# ARMv8M-Baseline register map
Registers are read-only, no defined reset value unless marked. A register's access mark holds for its fields unless they carry their own. Offsets are from the block's base; [hi:lo] are bit positions; {n}, {i} and the like mark numbered series.

## DWT — Data Watchpoint and Trace
Base 0xE0001000
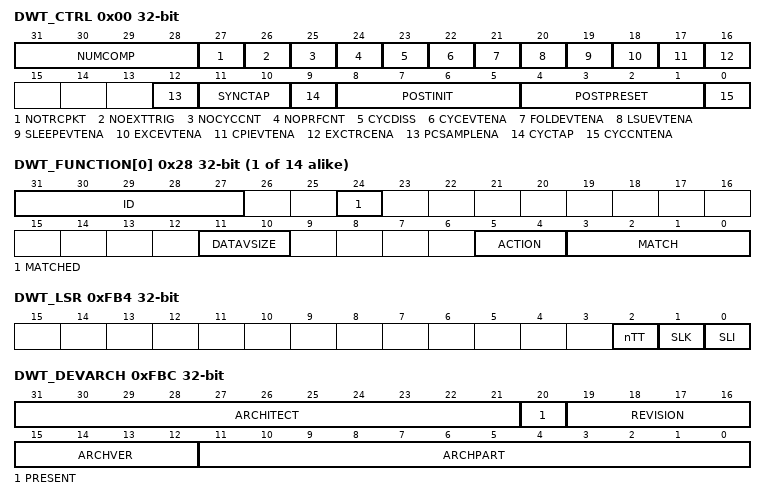
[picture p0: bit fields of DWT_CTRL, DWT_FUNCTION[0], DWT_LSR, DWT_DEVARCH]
0x00 DWT_CTRL rw — Data Watchpoint Trace Control Register provides configuration and status information and control of the unit
  [31:28] NUMCOMP — Number of comparators. Number of DWT comparators implemented
  [27] NOTRCPKT — No trace packets. Indicates whether the implementation does not support trace
    0=Trace supported; 1=Trace not supported
  [26] NOEXTTRIG — No External Triggers. Shows whether the implementation does not support external triggers
  [25] NOCYCCNT — No cycle count. Indicates whether the implementation does not include a cycle counter
    0=Cycle counter implemented; 1=Cycle counter not implemented
  [24] NOPRFCNT — No profile counters. Indicates whether the implementation does not include the profiling counters
    0=Profiling counters implemented; 1=Profiling counters not implemented
  [23] CYCDISS — Cycle counter disabled secure. Controls whether the cycle counter is disabled in Secure state
    0=No effect; 1=Disable incrementing of the cycle counter when the PE is in Secure state
  [22] CYCEVTENA — Cycle event enable. Enables Event Counter packet generation on POSTCNT underflow
    0=No Event Counter packets generated when POSTCNT underflows; 1=If PCSAMPLENA set to 0, an Event Counter packet is generated when POSTCNT underflows
  [21] FOLDEVTENA — Fold event enable. Enables DWT_FOLDCNT counter
    0=DWT_FOLDCNT disabled; 1=DWT_FOLDCNT enabled
  [20] LSUEVTENA — LSU event enable. Enables DWT_LSUCNT counter
    0=DWT_LSUCNT disabled; 1=DWT_LSUCNT enabled
  [19] SLEEPEVTENA — Sleep event enable. Enable DWT_SLEEPCNT counter
    0=DWT_SLEEPCNT disabled; 1=DWT_SLEEPCNT enabled
  [18] EXCEVTENA — Exception event enable. Enables DWT_EXCCNT counter
    0=DWT_EXCCNT disabled; 1=DWT_EXCCNT enabled
  [17] CPIEVTENA — CPI event enable. Enables DWT_CPICNT counter
    0=DWT_CPICNT disabled; 1=DWT_CPICNT enabled
  [16] EXCTRCENA — Exception trace enable. Enables generation of Exception Trace packets
    0=Exception Trace packet generation disabled; 1=Exception Trace packet generation enabled
  [12] PCSAMPLENA — PC sample enable
    0=Periodic PC Sample packet generation disabled; 1=Periodic PC Sample packet generated on POSTCNT underflow
  [11:10] SYNCTAP — Synchronization tap
    0=Synchronization packet generation disabled; 1=Synchronization counter tap at CYCCNT[24]; 2=Synchronization counter tap at CYCCNT[26]; 3=Synchronization counter tap at CYCCNT[28]
  [9] CYCTAP — Cycle count tap. Selects the position of the POSTCNT tap on the CYCCNT counter
    0=POSTCNT tap at CYCCNT[6]; 1=POSTCNT tap at CYCCNT[10]
  [8:5] POSTINIT — POSTCNT initial. Initial value for the POSTCNT counter
  [4:1] POSTPRESET — POSTCNT preset. Reload value for the POSTCNT counter
  [0] CYCCNTENA — CYCCNT enable. Enables CYCCNT
    0=CYCCNT disabled; 1=CYCCNT enabled
0x04 DWT_CYCCNT rw — DWT Cycle Count Register shows or sets the value of the processor cycle counter, CYCCNT
  [31:0] CYCCNT — Incrementing cycle counter value
0x08 DWT_CPICNT rw — DWT CPI Count Register counts additional cycles required to execute multicycle instructions and instruction fetch stalls
  [7:0] CPICNT — Base instruction overhead counter
0x0C DWT_EXCCNT rw — DWT Exception Overhead Count Register counts the total cycles spent in exception processing
  [7:0] EXCCNT — The exception overhead counter
0x10 DWT_SLEEPCNT rw — DWT Sleep Count Register counts the total number of cycles that the processor is sleeping
  [7:0] SLEEPCNT — Sleep counter
0x14 DWT_LSUCNT rw — DWT LSU Count Register increments on the additional cycles required to execute all load or store instructions
  [7:0] LSUCNT — Load-store overhead counter
0x18 DWT_FOLDCNT rw — DWT Folded Instruction Count Register increments on the additional cycles required to execute all load or store instructions
  [7:0] FOLDCNT — Folded instruction counter
0x1C DWT_PCSR — DWT Program Counter Sample Register samples the current value of the program counter
  [31:0] EIASAMPLE — Executed instruction address sample. Recently executed instruction address sample value
{0x20+0x10*i} DWT_COMP[{i}] (i=0..13) rw — Comparator register provides a reference value for use by watchpoint comparator n
  [31:1] PCVALUE — PC value. Reference value for comparison with program counter
  [31:0] CYCVALUE — Cycle value. Reference value for comparison with cycle count
  [31:0] DADDR — Data address. Reference value for comparison with load or store address
  [31:0] DVALUE — Data value. Reference value for comparison with load or store data
{0x28+0x10*i} DWT_FUNCTION[{i}] (i=0..13) rw — Data Watchpoint Trace Comparator Function Register
  [31:27] ID — Identify capability. Identifies the capabilities for MATCH for comparator n
    8=Data Address, and Data Address With Value; 9=Cycle Counter, Data Address, and Data Address With Value; 10=Instruction Address, Data Address, and Data Address With Value; 11=Cycle Counter, Instruction Address, Data Address and Data Address With Value; 24=Data Address, Data Address Limit, and Data Address With Value; 26=Instruction Address, Instruction Address Limit, Data Address, Data Address Limit, and Data Address With Value; 28=Data Address, Data Address Limit, Data Value, Linked Data Value, and Data Address With Value; 30=Instruction Address, Instruction Address Limit, Data Address, Data Address Limit, Data value, Linked Data Value, and Data Addre
  [24] MATCHED — Comparator matched. Set to 1 when the comparator matches
    0=No match; 1=Match. The comparator has matched since the last read of this register
  [11:10] DATAVSIZE — Data value size
    0=1 byte; 1=2 bytes; 2=4 bytes
  [5:4] ACTION — Action on match. Defines the action on a match
    0=Trigger only; 1=Generate debug event; 2=For a Cycle Counter, Instruction Address, Data Address, Data Value or Linked Data Value comparator, generate a Data Trace Match
  [3:0] MATCH — Match type. Controls the type of match generated by this comparator
    0=Disabled. Never generates a match; 1=Cycle Counter. Matches if DWT_CYCCNT equals the comparator value
0xFB0 DWT_LAR wo — DWT Software Lock Access Register provides CoreSight Software Lock control for the DWT, see the CoreSight Architecture Specification for details
  [31:0] KEY — Lock Access control
0xFB4 DWT_LSR — DWT Software Lock Status Register provides CoreSight Software Lock status information for the DWT, see the CoreSight Architecture Specification for details
  [2] nTT — Not thirty-two bit. See the CoreSight Architecture Specification
  [1] SLK — Software Lock status. See the CoreSight Architecture Specification
    0=Lock clear. Software writes are permitted to this component's registers; 1=Lock set
  [0] SLI — Software Lock implemented. See the CoreSight Architecture Specification
    0=Software Lock not implemented or debugger access; 1=Software Lock is implemented and software access
0xFBC DWT_DEVARCH — DWT Device Architecture Register provides CoreSight discovery information for the DWT
  [31:21] ARCHITECT — Architect. Defines the architect of the component
    0x23B=JEP106 continuation code 0x4, ID code 0x3B. ARM Limited
  [20] PRESENT — DEVARCH Present. Defines that the DEVARCH register is present
    1=DEVARCH information present
  [19:16] REVISION — Revision. Defines the architecture revision of the component
    0=DWT architecture v2.0
  [15:12] ARCHVER — Architecture Version. Defines the architecture version of the component
    1=DWT architecture v2
  [11:0] ARCHPART — Architecture Part. Defines the architecture of the component
    0xA02=DWT architecture
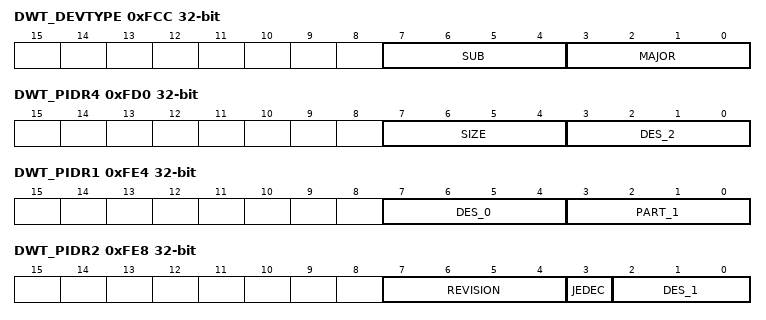
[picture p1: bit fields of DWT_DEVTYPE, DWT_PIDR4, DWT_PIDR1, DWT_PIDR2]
0xFCC DWT_DEVTYPE — DWT Device Type Register provides CoreSight discovery information for the DWT
  [7:4] SUB — Subtype. Component subtype
    0=Other
  [3:0] MAJOR — Major type. Component major type
    0=Miscellaneous
0xFD0 DWT_PIDR4 — DWT Peripheral Identification Register 4 provides CoreSight discovery information for the DWT
  [7:4] SIZE — 4KB count. See the CoreSight Architecture Specification
  [3:0] DES_2 — JEP106 continuation code. See the CoreSight Architecture Specification
{0xFC0+4i} DWT_PIDR{i} (i=5..7) — DWT Peripheral Identification Register {i} provides CoreSight discovery information for the DWT
0xFE0 DWT_PIDR0 — DWT Peripheral Identification Register 0 provides CoreSight discovery information for the DWT
  [7:0] PART_0 — Part number bits [7:0]. See the CoreSight Architecture Specification
0xFE4 DWT_PIDR1 — DWT Peripheral Identification Register 1 provides CoreSight discovery information for the DWT
  [7:4] DES_0 — JEP106 identification code bits [3:0]. See the CoreSight Architecture Specification
  [3:0] PART_1 — Part number bits [11:8]. See the CoreSight Architecture Specification
0xFE8 DWT_PIDR2 — DWT Peripheral Identification Register 2 provides CoreSight discovery information for the DWT
  [7:4] REVISION — Component revision. See the CoreSight Architecture Specification
  [3] JEDEC — JEDEC assignee value is used. See the CoreSight Architecture Specification
  [2:0] DES_1 — JEP106 identification code bits [6:4]. See the CoreSight Architecture Specification
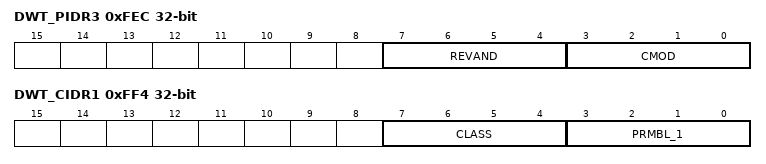
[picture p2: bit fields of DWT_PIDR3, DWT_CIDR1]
0xFEC DWT_PIDR3 — DWT Peripheral Identification Register 3 provides CoreSight discovery information for the DWT
  [7:4] REVAND — RevAnd. See the CoreSight Architecture Specification
  [3:0] CMOD — Customer Modified. See the CoreSight Architecture Specification
0xFF0 DWT_CIDR0 — DWT Component Identification Register 0 provides CoreSight discovery information for the DWT
  [7:0] PRMBL_0 — CoreSight component identification preamble
0xFF4 DWT_CIDR1 — DWT Component Identification Register 1 provides CoreSight discovery information for the DWT
  [7:4] CLASS — CoreSight component class. See the CoreSight Architecture Specification
  [3:0] PRMBL_1 — CoreSight component identification preamble
0xFF8 DWT_CIDR2 — DWT Component Identification Register 2 provides CoreSight discovery information for the DWT
  [7:0] PRMBL_2 — CoreSight component identification preamble
0xFFC DWT_CIDR3 — DWT Component Identification Register 3 provides CoreSight discovery information for the DWT
  [7:0] PRMBL_3 — CoreSight component identification preamble
